VERSION ""

NS_ :

BS_:

BU_: CN2 CN3
VAL_TABLE_ ID3 3 "Beschreibung für den Wert '0x3'" ;

BO_ 3221225472 VECTOR__INDEPENDENT_SIG_MSG: 0 Vector__XXX
 SG_ Red : 0|1@1+ (1,0) [0|1] "" Vector__XXX

BO_ 1 Hacked: 8 CN2

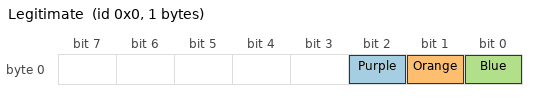
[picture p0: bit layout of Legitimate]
BO_ 0 Legitimate: 1 CN3
 SG_ Purple : 2|1@1+ (1,0) [0|1] "" Vector__XXX
 SG_ Orange : 1|1@1+ (1,0) [0|1] "" Vector__XXX
 SG_ Blue : 0|1@1+ (1,0) [0|1] "" Vector__XXX

EV_ StartBlue: 0 [0|1] "" 0 1 DUMMY_NODE_VECTOR3 Vector__XXX;

EV_ StartOrange: 0 [0|1] "" 0 2 DUMMY_NODE_VECTOR3 Vector__XXX;

EV_ StartRed: 0 [0|1] "" 0 3 DUMMY_NODE_VECTOR3 Vector__XXX;

EV_ StartPurple: 0 [0|1] "" 0 4 DUMMY_NODE_VECTOR3 Vector__XXX;

EV_ CANID: 0 [0|3] "" 0 5 DUMMY_NODE_VECTOR3 Vector__XXX;

CM_ BO_ 3221225472 "This is a message for not used signals, created by Vector CANdb++ DBC OLE DB Provider.";
